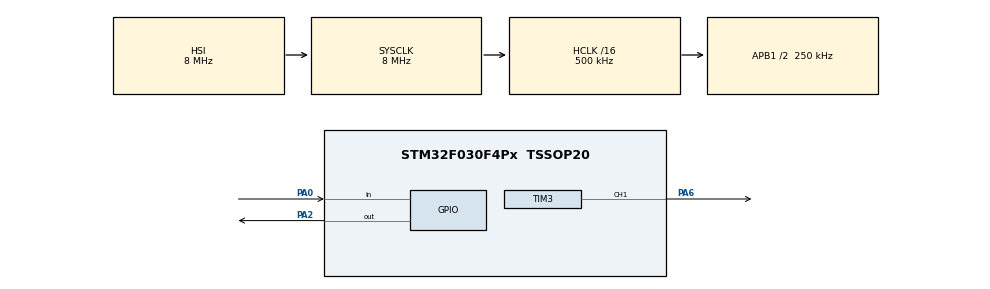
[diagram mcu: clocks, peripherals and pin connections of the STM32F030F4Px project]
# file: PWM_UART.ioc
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Mcu.Family=STM32F0
Mcu.Name=STM32F030F4Px
Mcu.Package=TSSOP20
NVIC.TIM14_IRQn=true\:0\:0\:false\:false\:true\:true\:true\:true
PA0.Signal=GPIO_Input
PA13.Mode=Serial_Wire
PA13.Signal=SYS_SWDIO
PA14.Mode=Serial_Wire
PA14.Signal=SYS_SWCLK
PA2.Signal=GPIO_Output
PA6.Signal=S_TIM3_CH1
PF0-OSC_IN.Mode=HSE-External-Oscillator
PF0-OSC_IN.Signal=RCC_OSC_IN
PF1-OSC_OUT.Mode=HSE-External-Oscillator
PF1-OSC_OUT.Signal=RCC_OSC_OUT
ProjectManager.HeapSize=0x200
ProjectManager.StackSize=0x400
ProjectManager.TargetToolchain=STM32CubeIDE
RCC.AHBCLKDivider=RCC_SYSCLK_DIV16
RCC.AHBFreq_Value=500000
RCC.APB1CLKDivider=RCC_HCLK_DIV2
RCC.APB1Freq_Value=250000
RCC.APB1TimFreq_Value=500000
RCC.HCLKFreq_Value=500000
RCC.HSE_VALUE=32000000
RCC.PLLDivider=RCC_PREDIV_DIV2
RCC.SYSCLKFreq_VALUE=8000000
SH.S_TIM3_CH1.0=TIM3_CH1,PWM Generation1 CH1
TIM14.AutoReloadPreload=TIM_AUTORELOAD_PRELOAD_ENABLE
TIM14.ClockDivision=TIM_CLOCKDIVISION_DIV1
TIM14.Period=50000-1
TIM14.Prescaler=0
TIM3.AutoReloadPreload=TIM_AUTORELOAD_PRELOAD_ENABLE
TIM3.Channel-PWM\ Generation1\ CH1=TIM_CHANNEL_1
TIM3.Period=555
TIM3.Pulse-PWM\ Generation1\ CH1=111
VP_TIM14_VS_ClockSourceINT.Mode=Enable_Timer
VP_TIM3_VS_ClockSourceINT.Mode=Internal
board=custom

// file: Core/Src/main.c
/* USER CODE BEGIN Header */
/**
  ******************************************************************************
  * @file           : main.c
  * @brief          : Main program body
  ******************************************************************************
  * @attention
  *
  * Copyright (c) 2024 STMicroelectronics.
  * All rights reserved.
  *
  * This software is licensed under terms that can be found in the LICENSE file
  * in the root directory of this software component.
  * If no LICENSE file comes with this software, it is provided AS-IS.
  *
  ******************************************************************************
  */
/* USER CODE END Header */
#include "main.h"

TIM_HandleTypeDef htim3;
TIM_HandleTypeDef htim14;
uint8_t botao_pressionado = 0; //Variável de controle (TIM3)
volatile uint8_t timer_expirou = 0; // Flag para indicar timeout (TIM14)

void SystemClock_Config(void);
static void MX_GPIO_Init(void);
static void MX_TIM3_Init(void);
static void MX_TIM14_Init(void);

int main(void)
{

  /* MCU Configuration--------------------------------------------------------*/

  /* Reset of all peripherals, Initializes the Flash interface and the Systick. */
  HAL_Init();

  /* Configure the system clock */
  SystemClock_Config();

  /* Initialize all configured peripherals */
  MX_GPIO_Init();
  MX_TIM3_Init();
  MX_TIM14_Init();
  /* USER CODE BEGIN 2 */

  //Iniciar o PWM (Timer 3 e canal 1)
  HAL_TIM_PWM_Start(&htim3, TIM_CHANNEL_1);
  HAL_TIM_Base_Start_IT(&htim14);

  // Valores de ARR (Auto-Reload Register) e passo de incremento (Parâmetros do PWM)
  uint32_t max_duty = __HAL_TIM_GET_AUTORELOAD(&htim3); // Valor máximo do ARR (555) - ARR armazena o valor máximo da contagem
  uint32_t step = 80;  // Incremento
  uint32_t duty = 0;   // Duty cycle inicial

  /* USER CODE END 2 */

  /* Infinite loop */
  /* USER CODE BEGIN WHILE */
  while (1)
  {
  	  	//Controle por flag que só registra 1 pressionamento após o botão ser pressionado
  		if(HAL_GPIO_ReadPin(GPIOA, GPIO_PIN_0)){

  			if (botao_pressionado == 0){ //Só registra o evento 1 vez, ou seja,

  				HAL_Delay(60); //Debounce

  				if(HAL_GPIO_ReadPin(GPIOA, GPIO_PIN_0)){ //Confirma o estado do botão

  					botao_pressionado = 1;

  					//Reiniciar o timer 14 (Time-out)
  					timer_expirou = 0; //Reseta a flag
  					HAL_TIM_Base_Stop_IT(&htim14); // Interrompe o timer
  					__HAL_TIM_SET_COUNTER(&htim14, 0); // Zera o contador (5s)
  					HAL_TIM_Base_Start_IT(&htim14);  // Inicia novamente o Timer14

  					duty += step;

  					//Reseta o Duty Cycle ao passar de 100%
  					if(duty > max_duty){

  						duty = 0; // Reinicia ao ultrapassar o valor máximo do ARR (555)
  					}

  					// Atualizar o duty cycle no CCR
  					__HAL_TIM_SET_COMPARE(&htim3, TIM_CHANNEL_1, duty);

  					HAL_Delay(20);
  				}
  			}
  		}

  		else{
  			botao_pressionado = 0;
  		}

  	    if (timer_expirou) //NÃO FUNCIONAL - Verifica o Timeout e ajuste do duty cycle para 10% (Se timer_expirou == 1)
  	    {
  	        // Ajusta o brilho para 10%
  	        uint32_t duty_10_percent = max_duty / 10; // 10% do valor máximo
  	        __HAL_TIM_SET_COMPARE(&htim3, TIM_CHANNEL_1, duty_10_percent);

  	        timer_expirou = 0; // reseta a flag
  	        HAL_TIM_Base_Stop_IT(&htim14); // Parar o timer para evitar reativação desnecessária
  	    }

    } //Fim do While
  /* USER CODE END 3 */
}

void HAL_TIM_PeriodElapsedCallback(TIM_HandleTypeDef *htim) // Função de Callback para alterar a flag
{
    if(htim->Instance == TIM14) // Verifica se a interrupção é do TIM14
    {
    	//HAL_GPIO_TogglePin(GPIOA, GPIO_PIN_2);
        timer_expirou = 1; // Marca que o timer expirou
    }
}

void SystemClock_Config(void)
{
  RCC_OscInitTypeDef RCC_OscInitStruct = {0};
  RCC_ClkInitTypeDef RCC_ClkInitStruct = {0};

  /** Initializes the RCC Oscillators according to the specified parameters
  * in the RCC_OscInitTypeDef structure.
  */
  RCC_OscInitStruct.OscillatorType = RCC_OSCILLATORTYPE_HSI;
  RCC_OscInitStruct.HSIState = RCC_HSI_ON;
  RCC_OscInitStruct.HSICalibrationValue = RCC_HSICALIBRATION_DEFAULT;
  RCC_OscInitStruct.PLL.PLLState = RCC_PLL_NONE;
  if (HAL_RCC_OscConfig(&RCC_OscInitStruct) != HAL_OK)
  {
    Error_Handler();
  }

  /** Initializes the CPU, AHB and APB buses clocks
  */
  RCC_ClkInitStruct.ClockType = RCC_CLOCKTYPE_HCLK|RCC_CLOCKTYPE_SYSCLK
                              |RCC_CLOCKTYPE_PCLK1;
  RCC_ClkInitStruct.SYSCLKSource = RCC_SYSCLKSOURCE_HSI;
  RCC_ClkInitStruct.AHBCLKDivider = RCC_SYSCLK_DIV16;
  RCC_ClkInitStruct.APB1CLKDivider = RCC_HCLK_DIV2;

  if (HAL_RCC_ClockConfig(&RCC_ClkInitStruct, FLASH_LATENCY_0) != HAL_OK)
  {
    Error_Handler();
  }
}

static void MX_TIM3_Init(void)
{

  TIM_ClockConfigTypeDef sClockSourceConfig = {0};
  TIM_MasterConfigTypeDef sMasterConfig = {0};
  TIM_OC_InitTypeDef sConfigOC = {0};

  htim3.Instance = TIM3;
  htim3.Init.Prescaler = 0;
  htim3.Init.CounterMode = TIM_COUNTERMODE_UP;
  htim3.Init.Period = 555;
  htim3.Init.ClockDivision = TIM_CLOCKDIVISION_DIV1;
  htim3.Init.AutoReloadPreload = TIM_AUTORELOAD_PRELOAD_ENABLE;
  if (HAL_TIM_Base_Init(&htim3) != HAL_OK)
  {
    Error_Handler();
  }
  sClockSourceConfig.ClockSource = TIM_CLOCKSOURCE_INTERNAL;
  if (HAL_TIM_ConfigClockSource(&htim3, &sClockSourceConfig) != HAL_OK)
  {
    Error_Handler();
  }
  if (HAL_TIM_PWM_Init(&htim3) != HAL_OK)
  {
    Error_Handler();
  }
  sMasterConfig.MasterOutputTrigger = TIM_TRGO_RESET;
  sMasterConfig.MasterSlaveMode = TIM_MASTERSLAVEMODE_DISABLE;
  if (HAL_TIMEx_MasterConfigSynchronization(&htim3, &sMasterConfig) != HAL_OK)
  {
    Error_Handler();
  }
  sConfigOC.OCMode = TIM_OCMODE_PWM1;
  sConfigOC.Pulse = 111;
  sConfigOC.OCPolarity = TIM_OCPOLARITY_HIGH;
  sConfigOC.OCFastMode = TIM_OCFAST_DISABLE;
  if (HAL_TIM_PWM_ConfigChannel(&htim3, &sConfigOC, TIM_CHANNEL_1) != HAL_OK)
  {
    Error_Handler();
  }
  HAL_TIM_MspPostInit(&htim3);

}

static void MX_TIM14_Init(void)
{

  htim14.Instance = TIM14;
  htim14.Init.Prescaler = 50-1;
  htim14.Init.CounterMode = TIM_COUNTERMODE_UP;
  htim14.Init.Period = 50000-1;
  htim14.Init.ClockDivision = TIM_CLOCKDIVISION_DIV1;
  htim14.Init.AutoReloadPreload = TIM_AUTORELOAD_PRELOAD_ENABLE;
  if (HAL_TIM_Base_Init(&htim14) != HAL_OK)
  {
    Error_Handler();
  }

}

static void MX_GPIO_Init(void)
{
  GPIO_InitTypeDef GPIO_InitStruct = {0};

  /* GPIO Ports Clock Enable */
  __HAL_RCC_GPIOF_CLK_ENABLE();
  __HAL_RCC_GPIOA_CLK_ENABLE();

  /*Configure GPIO pin Output Level */
  HAL_GPIO_WritePin(GPIOA, GPIO_PIN_2, GPIO_PIN_RESET);

  /*Configure GPIO pin : PA0 */
  GPIO_InitStruct.Pin = GPIO_PIN_0;
  GPIO_InitStruct.Mode = GPIO_MODE_INPUT;
  GPIO_InitStruct.Pull = GPIO_NOPULL;
  HAL_GPIO_Init(GPIOA, &GPIO_InitStruct);

  /*Configure GPIO pin : PA2 */
  GPIO_InitStruct.Pin = GPIO_PIN_2;
  GPIO_InitStruct.Mode = GPIO_MODE_OUTPUT_PP;
  GPIO_InitStruct.Pull = GPIO_NOPULL;
  GPIO_InitStruct.Speed = GPIO_SPEED_FREQ_LOW;
  HAL_GPIO_Init(GPIOA, &GPIO_InitStruct);

}

void Error_Handler(void)
{
  __disable_irq();
  while (1)
  {
  }
}
